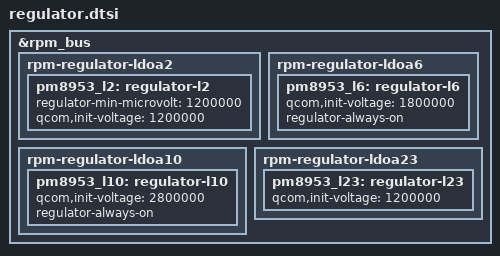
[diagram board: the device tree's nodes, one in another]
&rpm_bus {
	rpm-regulator-ldoa2 {
		pm8953_l2: regulator-l2 {
			regulator-min-microvolt = <1200000>;
			qcom,init-voltage = <1200000>;
		};
	};

	rpm-regulator-ldoa6 {
		pm8953_l6: regulator-l6 {
			qcom,init-voltage = <1800000>;
			regulator-always-on;
		};
	};

	rpm-regulator-ldoa10 {
		pm8953_l10: regulator-l10 {
			qcom,init-voltage = <2800000>;
			regulator-always-on;
		};
	};

    rpm-regulator-ldoa23 {
		pm8953_l23: regulator-l23 {
			qcom,init-voltage = <1200000>;
		};
	};
};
